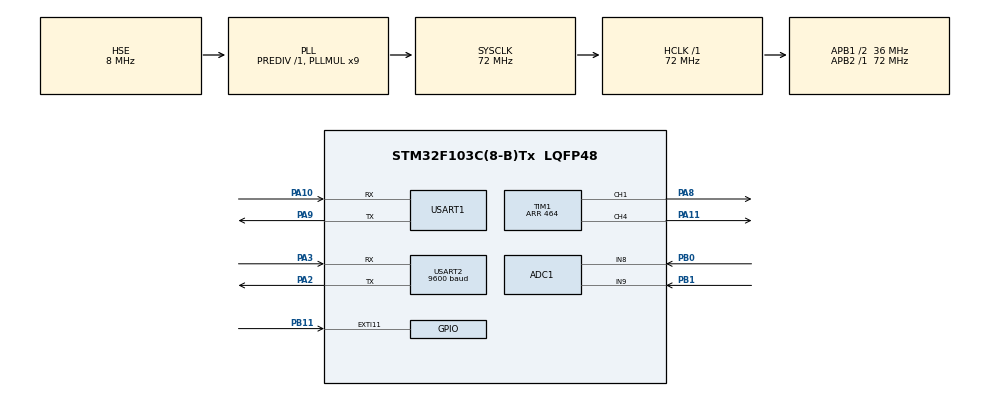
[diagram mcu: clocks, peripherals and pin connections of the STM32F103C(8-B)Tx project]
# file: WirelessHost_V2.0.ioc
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ADC1.Channel-0\#ChannelRegularConversion=ADC_CHANNEL_8
ADC1.NbrOfConversionFlag=1
ADC1.Rank-0\#ChannelRegularConversion=1
ADC1.SamplingTime-0\#ChannelRegularConversion=ADC_SAMPLETIME_1CYCLE_5
ADC1.master=1
Dma.Request0=USART2_TX
Dma.Request1=USART1_TX
Dma.USART1_TX.1.Direction=DMA_MEMORY_TO_PERIPH
Dma.USART1_TX.1.Instance=DMA1_Channel4
Dma.USART1_TX.1.MemDataAlignment=DMA_MDATAALIGN_BYTE
Dma.USART1_TX.1.MemInc=DMA_MINC_ENABLE
Dma.USART1_TX.1.Mode=DMA_NORMAL
Dma.USART1_TX.1.PeriphDataAlignment=DMA_PDATAALIGN_BYTE
Dma.USART1_TX.1.PeriphInc=DMA_PINC_DISABLE
Dma.USART1_TX.1.Priority=DMA_PRIORITY_LOW
Dma.USART2_TX.0.Direction=DMA_MEMORY_TO_PERIPH
Dma.USART2_TX.0.Instance=DMA1_Channel7
Dma.USART2_TX.0.MemDataAlignment=DMA_MDATAALIGN_BYTE
Dma.USART2_TX.0.MemInc=DMA_MINC_ENABLE
Dma.USART2_TX.0.Mode=DMA_NORMAL
Dma.USART2_TX.0.PeriphDataAlignment=DMA_PDATAALIGN_BYTE
Dma.USART2_TX.0.PeriphInc=DMA_PINC_DISABLE
Dma.USART2_TX.0.Priority=DMA_PRIORITY_LOW
Mcu.Family=STM32F1
Mcu.Name=STM32F103C(8-B)Tx
Mcu.Package=LQFP48
NVIC.DMA1_Channel4_IRQn=true\:3\:3\:true\:false\:true\:true\:true\:true
NVIC.DMA1_Channel7_IRQn=true\:3\:3\:true\:false\:true\:true\:true\:true
NVIC.EXTI15_10_IRQn=true\:0\:0\:true\:false\:true\:true\:true\:true
NVIC.PriorityGroup=NVIC_PRIORITYGROUP_2
NVIC.TIM2_IRQn=true\:0\:0\:true\:false\:true\:true\:true\:true
NVIC.TIM3_IRQn=true\:2\:2\:true\:false\:true\:true\:true\:true
NVIC.USART1_IRQn=true\:2\:2\:true\:false\:true\:true\:true\:true
NVIC.USART2_IRQn=true\:2\:2\:true\:false\:true\:true\:true\:true
PA10.Mode=Asynchronous
PA10.Signal=USART1_RX
PA11.Signal=S_TIM1_CH4
PA13.Mode=JTAG_4_pins
PA13.Signal=SYS_JTMS-SWDIO
PA14.Mode=JTAG_4_pins
PA14.Signal=SYS_JTCK-SWCLK
PA15.Mode=JTAG_4_pins
PA15.Signal=SYS_JTDI
PA2.Mode=Asynchronous
PA2.Signal=USART2_TX
PA3.GPIO_PuPd=GPIO_PULLUP
PA3.Mode=Asynchronous
PA3.Signal=USART2_RX
PA8.Signal=S_TIM1_CH1
PA9.Mode=Asynchronous
PA9.Signal=USART1_TX
PB0.Signal=ADCx_IN8
PB1.Signal=ADCx_IN9
PB11.GPIO_ModeDefaultEXTI=GPIO_MODE_IT_FALLING
PB11.GPIO_PuPd=GPIO_NOPULL
PB11.Signal=GPXTI11
PB3.Mode=JTAG_4_pins
PB3.Signal=SYS_JTDO-TRACESWO
PD0-OSC_IN.Mode=HSE-External-Oscillator
PD0-OSC_IN.Signal=RCC_OSC_IN
PD1-OSC_OUT.Mode=HSE-External-Oscillator
PD1-OSC_OUT.Signal=RCC_OSC_OUT
ProjectManager.HeapSize=0x200
ProjectManager.StackSize=0x400
ProjectManager.TargetToolchain=STM32CubeIDE
RCC.ADCPresc=RCC_ADCPCLK2_DIV8
RCC.AHBFreq_Value=72000000
RCC.APB1CLKDivider=RCC_HCLK_DIV2
RCC.APB1Freq_Value=36000000
RCC.APB1TimFreq_Value=72000000
RCC.APB2Freq_Value=72000000
RCC.APB2TimFreq_Value=72000000
RCC.HCLKFreq_Value=72000000
RCC.PLLMUL=RCC_PLL_MUL9
RCC.PLLSourceVirtual=RCC_PLLSOURCE_HSE
RCC.SYSCLKFreq_VALUE=72000000
RCC.SYSCLKSource=RCC_SYSCLKSOURCE_PLLCLK
RCC.USBFreq_Value=72000000
SH.ADCx_IN8.0=ADC1_IN8,IN8
SH.ADCx_IN9.0=ADC1_IN9,IN9
SH.S_TIM1_CH1.0=TIM1_CH1,PWM Generation1 CH1
SH.S_TIM1_CH4.0=TIM1_CH4,PWM Generation4 CH4
TIM1.AutoReloadPreload=TIM_AUTORELOAD_PRELOAD_ENABLE
TIM1.AutomaticOutput=TIM_AUTOMATICOUTPUT_ENABLE
TIM1.Channel-PWM\ Generation1\ CH1=TIM_CHANNEL_1
TIM1.Channel-PWM\ Generation4\ CH4=TIM_CHANNEL_4
TIM1.ClockDivision=TIM_CLOCKDIVISION_DIV1
TIM1.OCMode_PWM-PWM\ Generation4\ CH4=TIM_OCMODE_PWM2
TIM1.Period=464
TIM1.Pulse-PWM\ Generation1\ CH1=232
TIM1.Pulse-PWM\ Generation4\ CH4=232
TIM2.AutoReloadPreload=TIM_AUTORELOAD_PRELOAD_ENABLE
TIM2.Period=240
TIM2.Prescaler=8
TIM3.Period=4000
TIM3.Prescaler=71
USART1.VirtualMode=VM_ASYNC
USART2.BaudRate=9600
USART2.VirtualMode=VM_ASYNC
VP_TIM1_VS_ClockSourceINT.Mode=Internal
VP_TIM2_VS_ClockSourceINT.Mode=Internal
VP_TIM3_VS_ClockSourceINT.Mode=Internal
board=custom

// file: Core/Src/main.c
/* USER CODE BEGIN Header */
/**
  ******************************************************************************
  * @file           : main.c
  * @brief          : Main program body
  ******************************************************************************
  * @attention
  *
  * Copyright (c) 2024 STMicroelectronics.
  * All rights reserved.
  *
  * This software is licensed under terms that can be found in the LICENSE file
  * in the root directory of this software component.
  * If no LICENSE file comes with this software, it is provided AS-IS.
  *
  ******************************************************************************
  */
/* USER CODE END Header */
#include "main.h"

/* USER CODE BEGIN Includes */
#include "timer.h"
/* USER CODE END Includes */

ADC_HandleTypeDef hadc1;

TIM_HandleTypeDef htim1;
TIM_HandleTypeDef htim2;
TIM_HandleTypeDef htim3;

UART_HandleTypeDef huart1;
UART_HandleTypeDef huart2;
DMA_HandleTypeDef hdma_usart1_tx;
DMA_HandleTypeDef hdma_usart2_tx;

void SystemClock_Config(void);
static void MX_GPIO_Init(void);
static void MX_DMA_Init(void);
static void MX_ADC1_Init(void);
static void MX_TIM1_Init(void);
static void MX_USART1_UART_Init(void);
static void MX_USART2_UART_Init(void);
static void MX_TIM2_Init(void);
static void MX_TIM3_Init(void);

/* USER CODE BEGIN 0 */
uint8_t data[8] = {0x12, 0x34, 0x56, 0x78, 0x9A, 0xBC, 0xDE, 0xF0};
/* USER CODE END 0 */

int main(void)
{

  /* MCU Configuration--------------------------------------------------------*/

  /* Reset of all peripherals, Initializes the Flash interface and the Systick. */
  HAL_Init();

  /* Configure the system clock */
  SystemClock_Config();

  /* Initialize all configured peripherals */
  MX_GPIO_Init();
  MX_DMA_Init();
  MX_ADC1_Init();
  MX_TIM1_Init();
  MX_USART1_UART_Init();
  MX_USART2_UART_Init();
  MX_TIM2_Init();
  MX_TIM3_Init();
  /* USER CODE BEGIN 2 */
  HAL_TIM_PWM_Start(&htim1, TIM_CHANNEL_1);
  HAL_TIM_PWM_Start(&htim1, TIM_CHANNEL_4);
  change_out_frequence(150000);//改变输出频率
  bpm_init();
  bpm_receive();
  /* USER CODE END 2 */

  /* Infinite loop */
  /* USER CODE BEGIN WHILE */
  while (1)
  {
	  bpm_receive();
    /* USER CODE END WHILE */

    /* USER CODE BEGIN 3 */
//	HAL_UART_Transmit(&huart1, &data[0], 5,1000) ;
//	HAL_Delay(50);
//	HAL_UART_Transmit_DMA(&huart2, &data[0], 8) ;
//	HAL_Delay(500);
  }
  /* USER CODE END 3 */
}

void SystemClock_Config(void)
{
  RCC_OscInitTypeDef RCC_OscInitStruct = {0};
  RCC_ClkInitTypeDef RCC_ClkInitStruct = {0};
  RCC_PeriphCLKInitTypeDef PeriphClkInit = {0};

  /** Initializes the RCC Oscillators according to the specified parameters
  * in the RCC_OscInitTypeDef structure.
  */
  RCC_OscInitStruct.OscillatorType = RCC_OSCILLATORTYPE_HSE;
  RCC_OscInitStruct.HSEState = RCC_HSE_ON;
  RCC_OscInitStruct.HSEPredivValue = RCC_HSE_PREDIV_DIV1;
  RCC_OscInitStruct.HSIState = RCC_HSI_ON;
  RCC_OscInitStruct.PLL.PLLState = RCC_PLL_ON;
  RCC_OscInitStruct.PLL.PLLSource = RCC_PLLSOURCE_HSE;
  RCC_OscInitStruct.PLL.PLLMUL = RCC_PLL_MUL9;
  if (HAL_RCC_OscConfig(&RCC_OscInitStruct) != HAL_OK)
  {
    Error_Handler();
  }

  /** Initializes the CPU, AHB and APB buses clocks
  */
  RCC_ClkInitStruct.ClockType = RCC_CLOCKTYPE_HCLK|RCC_CLOCKTYPE_SYSCLK
                              |RCC_CLOCKTYPE_PCLK1|RCC_CLOCKTYPE_PCLK2;
  RCC_ClkInitStruct.SYSCLKSource = RCC_SYSCLKSOURCE_PLLCLK;
  RCC_ClkInitStruct.AHBCLKDivider = RCC_SYSCLK_DIV1;
  RCC_ClkInitStruct.APB1CLKDivider = RCC_HCLK_DIV2;
  RCC_ClkInitStruct.APB2CLKDivider = RCC_HCLK_DIV1;

  if (HAL_RCC_ClockConfig(&RCC_ClkInitStruct, FLASH_LATENCY_2) != HAL_OK)
  {
    Error_Handler();
  }
  PeriphClkInit.PeriphClockSelection = RCC_PERIPHCLK_ADC;
  PeriphClkInit.AdcClockSelection = RCC_ADCPCLK2_DIV8;
  if (HAL_RCCEx_PeriphCLKConfig(&PeriphClkInit) != HAL_OK)
  {
    Error_Handler();
  }
}

static void MX_ADC1_Init(void)
{

  ADC_ChannelConfTypeDef sConfig = {0};

  /** Common config
  */
  hadc1.Instance = ADC1;
  hadc1.Init.ScanConvMode = ADC_SCAN_DISABLE;
  hadc1.Init.ContinuousConvMode = DISABLE;
  hadc1.Init.DiscontinuousConvMode = DISABLE;
  hadc1.Init.ExternalTrigConv = ADC_SOFTWARE_START;
  hadc1.Init.DataAlign = ADC_DATAALIGN_RIGHT;
  hadc1.Init.NbrOfConversion = 1;
  if (HAL_ADC_Init(&hadc1) != HAL_OK)
  {
    Error_Handler();
  }

  /** Configure Regular Channel
  */
  sConfig.Channel = ADC_CHANNEL_8;
  sConfig.Rank = ADC_REGULAR_RANK_1;
  sConfig.SamplingTime = ADC_SAMPLETIME_1CYCLE_5;
  if (HAL_ADC_ConfigChannel(&hadc1, &sConfig) != HAL_OK)
  {
    Error_Handler();
  }

}

static void MX_TIM1_Init(void)
{

  TIM_ClockConfigTypeDef sClockSourceConfig = {0};
  TIM_MasterConfigTypeDef sMasterConfig = {0};
  TIM_OC_InitTypeDef sConfigOC = {0};
  TIM_BreakDeadTimeConfigTypeDef sBreakDeadTimeConfig = {0};

  htim1.Instance = TIM1;
  htim1.Init.Prescaler = 0;
  htim1.Init.CounterMode = TIM_COUNTERMODE_UP;
  htim1.Init.Period = 464;
  htim1.Init.ClockDivision = TIM_CLOCKDIVISION_DIV1;
  htim1.Init.RepetitionCounter = 0;
  htim1.Init.AutoReloadPreload = TIM_AUTORELOAD_PRELOAD_ENABLE;
  if (HAL_TIM_Base_Init(&htim1) != HAL_OK)
  {
    Error_Handler();
  }
  sClockSourceConfig.ClockSource = TIM_CLOCKSOURCE_INTERNAL;
  if (HAL_TIM_ConfigClockSource(&htim1, &sClockSourceConfig) != HAL_OK)
  {
    Error_Handler();
  }
  if (HAL_TIM_PWM_Init(&htim1) != HAL_OK)
  {
    Error_Handler();
  }
  sMasterConfig.MasterOutputTrigger = TIM_TRGO_RESET;
  sMasterConfig.MasterSlaveMode = TIM_MASTERSLAVEMODE_DISABLE;
  if (HAL_TIMEx_MasterConfigSynchronization(&htim1, &sMasterConfig) != HAL_OK)
  {
    Error_Handler();
  }
  sConfigOC.OCMode = TIM_OCMODE_PWM1;
  sConfigOC.Pulse = 232;
  sConfigOC.OCPolarity = TIM_OCPOLARITY_HIGH;
  sConfigOC.OCNPolarity = TIM_OCNPOLARITY_HIGH;
  sConfigOC.OCFastMode = TIM_OCFAST_DISABLE;
  sConfigOC.OCIdleState = TIM_OCIDLESTATE_RESET;
  sConfigOC.OCNIdleState = TIM_OCNIDLESTATE_RESET;
  if (HAL_TIM_PWM_ConfigChannel(&htim1, &sConfigOC, TIM_CHANNEL_1) != HAL_OK)
  {
    Error_Handler();
  }
  sConfigOC.OCMode = TIM_OCMODE_PWM2;
  if (HAL_TIM_PWM_ConfigChannel(&htim1, &sConfigOC, TIM_CHANNEL_4) != HAL_OK)
  {
    Error_Handler();
  }
  sBreakDeadTimeConfig.OffStateRunMode = TIM_OSSR_DISABLE;
  sBreakDeadTimeConfig.OffStateIDLEMode = TIM_OSSI_DISABLE;
  sBreakDeadTimeConfig.LockLevel = TIM_LOCKLEVEL_OFF;
  sBreakDeadTimeConfig.DeadTime = 0;
  sBreakDeadTimeConfig.BreakState = TIM_BREAK_DISABLE;
  sBreakDeadTimeConfig.BreakPolarity = TIM_BREAKPOLARITY_HIGH;
  sBreakDeadTimeConfig.AutomaticOutput = TIM_AUTOMATICOUTPUT_ENABLE;
  if (HAL_TIMEx_ConfigBreakDeadTime(&htim1, &sBreakDeadTimeConfig) != HAL_OK)
  {
    Error_Handler();
  }
  HAL_TIM_MspPostInit(&htim1);

}

static void MX_TIM2_Init(void)
{

  TIM_ClockConfigTypeDef sClockSourceConfig = {0};
  TIM_MasterConfigTypeDef sMasterConfig = {0};

  htim2.Instance = TIM2;
  htim2.Init.Prescaler = 8;
  htim2.Init.CounterMode = TIM_COUNTERMODE_UP;
  htim2.Init.Period = 240;
  htim2.Init.ClockDivision = TIM_CLOCKDIVISION_DIV1;
  htim2.Init.AutoReloadPreload = TIM_AUTORELOAD_PRELOAD_ENABLE;
  if (HAL_TIM_Base_Init(&htim2) != HAL_OK)
  {
    Error_Handler();
  }
  sClockSourceConfig.ClockSource = TIM_CLOCKSOURCE_INTERNAL;
  if (HAL_TIM_ConfigClockSource(&htim2, &sClockSourceConfig) != HAL_OK)
  {
    Error_Handler();
  }
  sMasterConfig.MasterOutputTrigger = TIM_TRGO_RESET;
  sMasterConfig.MasterSlaveMode = TIM_MASTERSLAVEMODE_DISABLE;
  if (HAL_TIMEx_MasterConfigSynchronization(&htim2, &sMasterConfig) != HAL_OK)
  {
    Error_Handler();
  }

}

static void MX_TIM3_Init(void)
{

  TIM_ClockConfigTypeDef sClockSourceConfig = {0};
  TIM_MasterConfigTypeDef sMasterConfig = {0};

  htim3.Instance = TIM3;
  htim3.Init.Prescaler = 71;
  htim3.Init.CounterMode = TIM_COUNTERMODE_UP;
  htim3.Init.Period = 4000;
  htim3.Init.ClockDivision = TIM_CLOCKDIVISION_DIV1;
  htim3.Init.AutoReloadPreload = TIM_AUTORELOAD_PRELOAD_DISABLE;
  if (HAL_TIM_Base_Init(&htim3) != HAL_OK)
  {
    Error_Handler();
  }
  sClockSourceConfig.ClockSource = TIM_CLOCKSOURCE_INTERNAL;
  if (HAL_TIM_ConfigClockSource(&htim3, &sClockSourceConfig) != HAL_OK)
  {
    Error_Handler();
  }
  sMasterConfig.MasterOutputTrigger = TIM_TRGO_RESET;
  sMasterConfig.MasterSlaveMode = TIM_MASTERSLAVEMODE_DISABLE;
  if (HAL_TIMEx_MasterConfigSynchronization(&htim3, &sMasterConfig) != HAL_OK)
  {
    Error_Handler();
  }

}

static void MX_USART1_UART_Init(void)
{

  huart1.Instance = USART1;
  huart1.Init.BaudRate = 115200;
  huart1.Init.WordLength = UART_WORDLENGTH_8B;
  huart1.Init.StopBits = UART_STOPBITS_1;
  huart1.Init.Parity = UART_PARITY_NONE;
  huart1.Init.Mode = UART_MODE_TX_RX;
  huart1.Init.HwFlowCtl = UART_HWCONTROL_NONE;
  huart1.Init.OverSampling = UART_OVERSAMPLING_16;
  if (HAL_UART_Init(&huart1) != HAL_OK)
  {
    Error_Handler();
  }

}

static void MX_USART2_UART_Init(void)
{

  huart2.Instance = USART2;
  huart2.Init.BaudRate = 9600;
  huart2.Init.WordLength = UART_WORDLENGTH_8B;
  huart2.Init.StopBits = UART_STOPBITS_1;
  huart2.Init.Parity = UART_PARITY_NONE;
  huart2.Init.Mode = UART_MODE_TX_RX;
  huart2.Init.HwFlowCtl = UART_HWCONTROL_NONE;
  huart2.Init.OverSampling = UART_OVERSAMPLING_16;
  if (HAL_UART_Init(&huart2) != HAL_OK)
  {
    Error_Handler();
  }

}

static void MX_DMA_Init(void)
{

  /* DMA controller clock enable */
  __HAL_RCC_DMA1_CLK_ENABLE();

  /* DMA interrupt init */
  /* DMA1_Channel4_IRQn interrupt configuration */
  HAL_NVIC_SetPriority(DMA1_Channel4_IRQn, 3, 3);
  HAL_NVIC_EnableIRQ(DMA1_Channel4_IRQn);
  /* DMA1_Channel7_IRQn interrupt configuration */
  HAL_NVIC_SetPriority(DMA1_Channel7_IRQn, 3, 3);
  HAL_NVIC_EnableIRQ(DMA1_Channel7_IRQn);

}

static void MX_GPIO_Init(void)
{
  GPIO_InitTypeDef GPIO_InitStruct = {0};

  /* GPIO Ports Clock Enable */
  __HAL_RCC_GPIOD_CLK_ENABLE();
  __HAL_RCC_GPIOA_CLK_ENABLE();
  __HAL_RCC_GPIOB_CLK_ENABLE();

  /*Configure GPIO pin : PB11 */
  GPIO_InitStruct.Pin = GPIO_PIN_11;
  GPIO_InitStruct.Mode = GPIO_MODE_IT_FALLING;
  GPIO_InitStruct.Pull = GPIO_NOPULL;
  HAL_GPIO_Init(GPIOB, &GPIO_InitStruct);

  /* EXTI interrupt init*/
  HAL_NVIC_SetPriority(EXTI15_10_IRQn, 0, 0);
  HAL_NVIC_EnableIRQ(EXTI15_10_IRQn);

}

void Error_Handler(void)
{
  __disable_irq();
  while (1)
  {
  }
}
